# STM32L053xx register map
File version: 1.0
Registers are 32-bit, read-write, reset 0x0 unless marked. A register's access mark holds for its fields unless they carry their own. Offsets are from the block's base; [hi:lo] are bit positions; 'fields as' and 'values as' point back to an identical list.

## COMP1 — Comparator
Base 0x40010018
Same registers: COMP2 0x4001001C
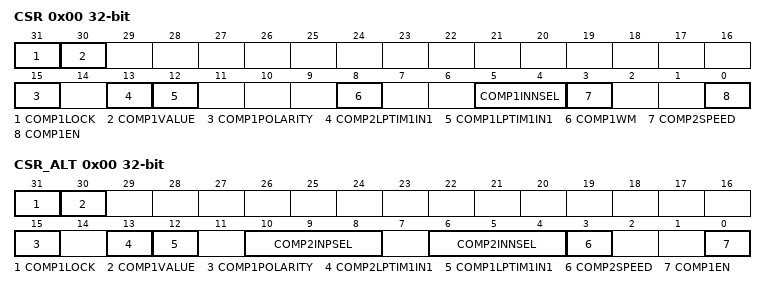
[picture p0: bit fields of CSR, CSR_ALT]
0x00 CSR — COMP comparator control and status register
  [31] COMP1LOCK
  [30] COMP1VALUE — COMP1 output level
  [15] COMP1POLARITY — COMP1 output polarity
  [13] COMP2LPTIM1IN1 — COMP2 LPTIM1 IN1 connection
  [12] COMP1LPTIM1IN1 — COMP1 LPTIM1 IN1 connection
  [8] COMP1WM — Comparators window mode enable
    0=DISABLE (Window mode disable: Comparators 1 and 2 are independent); 1=COMP1_INPUT_PLUS_COMMON (Window mode enable: Comparators instances pair COMP1 and COMP2 have their input plus connected together. The common input is COMP1 input plus (COMP2 input plus is no more accessible).)
  [5:4] COMP1INNSEL — COMP1 inverting input select
  [3] COMP2SPEED — COMP2 power mode
    1=MEDIUMSPEED (COMP power mode to fast speed (specific to COMP instance: COMP2)); 0=ULTRALOWPOWER (COMP power mode to low speed (specific to COMP instance: COMP2))
  [0] COMP1EN — COMP1 enable
0x00 CSR_ALT (alternate view of CSR) — COMP comparator control and status register
  [31] COMP1LOCK
  [30] COMP1VALUE — COMP1 output level
  [15] COMP1POLARITY — COMP1 output polarity
  [13] COMP2LPTIM1IN1 — COMP2 LPTIM1 IN1 connection
  [12] COMP1LPTIM1IN1 — COMP1 LPTIM1 IN1 connection
  [10:8] COMP2INPSEL — COMPx non inverting input select
    0=IO1 (Comparator input plus connected to IO1 (pin PA1 for COMP1, pin PA3 for COMP2)); 1=IO2 (Comparator input plus connected to IO2 (pin PB4 for COMP2) (specific to COMP instance: COMP2)); 2=IO3 (Comparator input plus connected to IO3 (pin PA5 for COMP2) (specific to COMP instance: COMP2)); 3=IO4 (Comparator input plus connected to IO4 (pin PB6 for COMP2) (specific to COMP instance: COMP2)); 4=IO5 (Comparator input plus connected to IO5 (pin PB7 for COMP2) (specific to COMP instance: COMP2))
  [6:4] COMP2INNSEL — COMP2 inverting input select
    0=VREFINT (Comparator input minus connected to VrefInt (specifity of COMP2 related to path to enable via SYSCFG: refer to comment in function @ref LL_COMP_SetInputMinus() )); 1=IO1 (Comparator input minus connected to IO1 (pin PA0 for COMP1, pin PA2 for COMP2)); 2=DAC1_CH1 (Comparator input minus connected to DAC1 channel 1 (DAC_OUT1)); 3=DAC1_CH2 (Comparator input minus connected to DAC1 channel 2 (DAC_OUT2)); 4=MINUS_1_4VREFINT (Comparator input minus connected to 1/4 VrefInt (specifity of COMP2 related to path to enable via SYSCFG: refer to comment in function @ref LL_COMP_SetInputMinus() ) (specific to COMP instance: COMP2)); 5=MINUS_1_2VREFINT (Comparator input minus connected to 1/2 VrefInt (specifity of COMP2 related to path to enable via SYSCFG: refer to comment in function @ref LL_COMP_SetInputMinus() ) (specific to COMP instance: COMP2)); 6=MINUS_3_4VREFINT (Comparator input minus connected to 3/4 VrefInt (specifity of COMP2 related to path to enable via SYSCFG: refer to comment in function @ref LL_COMP_SetInputMinus() ) (specific to COMP instance: COMP2)); 7=IO2 (Comparator input minus connected to IO2 (pin PB3 for COMP2) (specific to COMP instance: COMP2))
  [3] COMP2SPEED — COMP2 power mode
    values as CSR.COMP2SPEED
  [0] COMP1EN — COMP1 enable

## COMP12_COMMON
Base 0x40010018; alternate view of COMP1
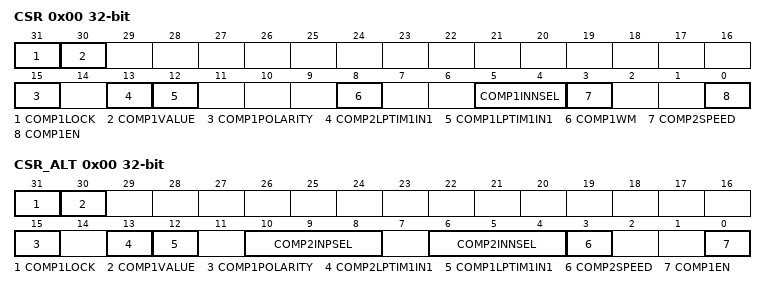
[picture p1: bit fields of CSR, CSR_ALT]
0x00 CSR — COMP control and status register, used for bits common to several COMP instances
  [31] COMP1LOCK
  [30] COMP1VALUE — COMP1 output level
  [15] COMP1POLARITY — COMP1 output polarity
  [13] COMP2LPTIM1IN1 — COMP2 LPTIM1 IN1 connection
  [12] COMP1LPTIM1IN1 — COMP1 LPTIM1 IN1 connection
  [8] COMP1WM — Comparators window mode enable
    0=DISABLE (Window mode disable: Comparators 1 and 2 are independent); 1=COMP1_INPUT_PLUS_COMMON (Window mode enable: Comparators instances pair COMP1 and COMP2 have their input plus connected together. The common input is COMP1 input plus (COMP2 input plus is no more accessible).)
  [5:4] COMP1INNSEL — COMP1 inverting input select
  [3] COMP2SPEED — COMP2 power mode
    1=MEDIUMSPEED (COMP power mode to fast speed (specific to COMP instance: COMP2)); 0=ULTRALOWPOWER (COMP power mode to low speed (specific to COMP instance: COMP2))
  [0] COMP1EN — COMP1 enable
0x00 CSR_ALT (alternate view of CSR) — COMP control and status register, used for bits common to several COMP instances
  [31] COMP1LOCK
  [30] COMP1VALUE — COMP1 output level
  [15] COMP1POLARITY — COMP1 output polarity
  [13] COMP2LPTIM1IN1 — COMP2 LPTIM1 IN1 connection
  [12] COMP1LPTIM1IN1 — COMP1 LPTIM1 IN1 connection
  [10:8] COMP2INPSEL — COMPx non inverting input select
    0=IO1 (Comparator input plus connected to IO1 (pin PA1 for COMP1, pin PA3 for COMP2)); 1=IO2 (Comparator input plus connected to IO2 (pin PB4 for COMP2) (specific to COMP instance: COMP2)); 2=IO3 (Comparator input plus connected to IO3 (pin PA5 for COMP2) (specific to COMP instance: COMP2)); 3=IO4 (Comparator input plus connected to IO4 (pin PB6 for COMP2) (specific to COMP instance: COMP2)); 4=IO5 (Comparator input plus connected to IO5 (pin PB7 for COMP2) (specific to COMP instance: COMP2))
  [6:4] COMP2INNSEL — COMP2 inverting input select
    0=VREFINT (Comparator input minus connected to VrefInt (specifity of COMP2 related to path to enable via SYSCFG: refer to comment in function @ref LL_COMP_SetInputMinus() )); 1=IO1 (Comparator input minus connected to IO1 (pin PA0 for COMP1, pin PA2 for COMP2)); 2=DAC1_CH1 (Comparator input minus connected to DAC1 channel 1 (DAC_OUT1)); 3=DAC1_CH2 (Comparator input minus connected to DAC1 channel 2 (DAC_OUT2)); 4=MINUS_1_4VREFINT (Comparator input minus connected to 1/4 VrefInt (specifity of COMP2 related to path to enable via SYSCFG: refer to comment in function @ref LL_COMP_SetInputMinus() ) (specific to COMP instance: COMP2)); 5=MINUS_1_2VREFINT (Comparator input minus connected to 1/2 VrefInt (specifity of COMP2 related to path to enable via SYSCFG: refer to comment in function @ref LL_COMP_SetInputMinus() ) (specific to COMP instance: COMP2)); 6=MINUS_3_4VREFINT (Comparator input minus connected to 3/4 VrefInt (specifity of COMP2 related to path to enable via SYSCFG: refer to comment in function @ref LL_COMP_SetInputMinus() ) (specific to COMP instance: COMP2)); 7=IO2 (Comparator input minus connected to IO2 (pin PB3 for COMP2) (specific to COMP instance: COMP2))
  [3] COMP2SPEED — COMP2 power mode
    values as CSR.COMP2SPEED
  [0] COMP1EN — COMP1 enable
